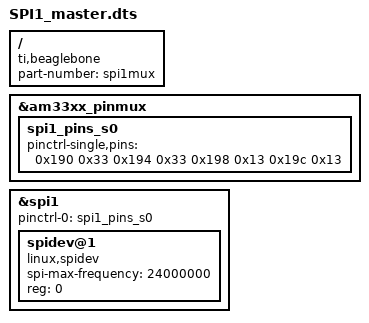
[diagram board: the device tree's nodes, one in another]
/dts-v1/;
/plugin/;

/* SPI1 */
/* D1 Output and D0 Input */

/ {
    compatible = "ti,beaglebone", "ti,beaglebone-black";

    /* identification */
    part-number = "spi1mux";

    fragment@0 {
        target = <&am33xx_pinmux>;
        __overlay__ {
            spi1_pins_s0: spi1_pins_s0 {
                        pinctrl-single,pins = <
                                0x190 0x33      /* spi1_sclk, INPUT_PULLUP  | MODE3 */
                                0x194 0x33      /* spi1_d0,   INPUT_PULLUP  | MODE3 */
                                0x198 0x13      /* spi1_d1,   OUTPUT_PULLUP | MODE3 */
                                0x19c 0x13      /* spi1_cs0,  OUTPUT_PULLUP | MODE3 */
                >;
            };
        };
    };

    fragment@1 {
        target = <&spi1>;
        __overlay__ {

             #address-cells = <1>;
             #size-cells = <0>;
             status = "okay";
             pinctrl-names = "default";
             pinctrl-0 = <&spi1_pins_s0>;

             spidev@1 {
                 spi-max-frequency = <24000000>;
                 reg = <0>;
                 compatible = "linux,spidev";
            };
        };
    };
};
